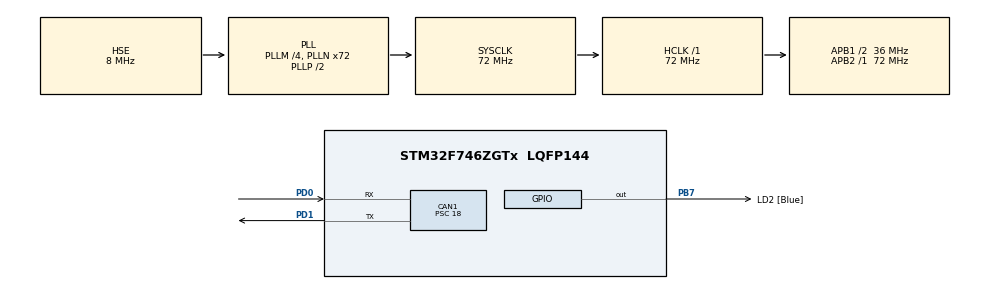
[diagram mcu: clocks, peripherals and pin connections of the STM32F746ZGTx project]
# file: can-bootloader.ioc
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CAN1.BS1=CAN_BS1_13TQ
CAN1.BS2=CAN_BS2_2TQ
CAN1.CalculateBaudRate=125000
CAN1.CalculateTimeBit=8000
CAN1.CalculateTimeQuantum=500.0
CAN1.NART=ENABLE
CAN1.Prescaler=18
CORTEX_M7.default_mode_Activation=1
CRC.InputDataFormat=CRC_INPUTDATA_FORMAT_WORDS
Mcu.Family=STM32F7
Mcu.Name=STM32F746ZGTx
Mcu.Package=LQFP144
NVIC.CAN1_RX0_IRQn=true\:0\:0\:false\:false\:true\:true\:true\:true
NVIC.CAN1_TX_IRQn=true\:0\:0\:false\:false\:true\:true\:true\:true
NVIC.PriorityGroup=NVIC_PRIORITYGROUP_4
NVIC.TIM6_DAC_IRQn=true\:0\:0\:false\:false\:true\:true\:true\:true
PA13.GPIO_Label=TMS
PA13.Mode=Serial_Wire
PA13.Signal=SYS_JTMS-SWDIO
PA14.GPIO_Label=TCK
PA14.Mode=Serial_Wire
PA14.Signal=SYS_JTCK-SWCLK
PB7.GPIO_Label=LD2 [Blue]
PB7.Signal=GPIO_Output
PD0.Mode=CAN_Activate
PD0.Signal=CAN1_RX
PD1.Mode=CAN_Activate
PD1.Signal=CAN1_TX
PH0/OSC_IN.GPIO_Label=MCO [STM32F103CBT6_PA8]
PH0/OSC_IN.Mode=HSE-External-Clock-Source
PH0/OSC_IN.Signal=RCC_OSC_IN
PH1/OSC_OUT.Mode=HSE-External-Clock-Source
PH1/OSC_OUT.Signal=RCC_OSC_OUT
ProjectManager.HeapSize=0x200
ProjectManager.StackSize=0x400
ProjectManager.TargetToolchain=CMake
RCC.48MHZClocksFreq_Value=24000000
RCC.AHBFreq_Value=72000000
RCC.APB1CLKDivider=RCC_HCLK_DIV2
RCC.APB1Freq_Value=36000000
RCC.APB1TimFreq_Value=72000000
RCC.APB2Freq_Value=72000000
RCC.APB2TimFreq_Value=72000000
RCC.CortexFreq_Value=72000000
RCC.HCLKFreq_Value=72000000
RCC.HSE_VALUE=8000000
RCC.HSI_VALUE=16000000
RCC.LSE_VALUE=32768
RCC.PLLM=4
RCC.PLLMUL=RCC_PLL_MUL9
RCC.PLLN=72
RCC.PLLQ=3
RCC.PLLSourceVirtual=RCC_PLLSOURCE_HSE
RCC.PRESCALERUSB=RCC_USBCLKSOURCE_PLL_DIV1_5
RCC.SYSCLKFreq_VALUE=72000000
RCC.SYSCLKSource=RCC_SYSCLKSOURCE_PLLCLK
RCC.SYSCLKSourceVirtual=RCC_SYSCLKSOURCE_PLLCLK
RCC.USBFreq_Value=48000000
RCC.VCOOutputFreq_Value=144000000
TIM6.Period=49999
TIM6.Prescaler=7199
VP_CRC_VS_CRC.Mode=CRC_Activate
VP_TIM6_VS_ClockSourceINT.Mode=Enable_Timer
board=NUCLEO-F746ZG

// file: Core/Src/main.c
/* USER CODE BEGIN Header */
/**
  ******************************************************************************
  * @file           : main.c
  * @brief          : Main program body
  ******************************************************************************
  * @attention
  *
  * Copyright (c) 2026 STMicroelectronics.
  * All rights reserved.
  *
  * This software is licensed under terms that can be found in the LICENSE file
  * in the root directory of this software component.
  * If no LICENSE file comes with this software, it is provided AS-IS.
  *
  ******************************************************************************
  */
/* USER CODE END Header */
#include "main.h"

/* USER CODE BEGIN Includes */
#include "boot_utility.h"
#include "can_utility.h"
#include "flash_utility.h"
#include "string.h"
/* USER CODE END Includes */

CAN_HandleTypeDef hcan1;

CRC_HandleTypeDef hcrc;

TIM_HandleTypeDef htim6;

void SystemClock_Config(void);
static void MPU_Config(void);
static void MX_GPIO_Init(void);
static void MX_CAN1_Init(void);
static void MX_TIM6_Init(void);
static void MX_CRC_Init(void);

/* USER CODE BEGIN 0 */
// If timer gets reset, it means no CAN frame arrived in the last 5s
void HAL_TIM_PeriodElapsedCallback(TIM_HandleTypeDef *htim)
{
  if (htim->Instance == TIM6)
  {
    abort_required = 1;
  }
}
/* USER CODE END 0 */

int main(void)
{

  /* USER CODE BEGIN 1 */
  HAL_StatusTypeDef res;
  /* USER CODE END 1 */

  /* MPU Configuration--------------------------------------------------------*/
  MPU_Config();

  /* MCU Configuration--------------------------------------------------------*/

  /* Reset of all peripherals, Initializes the Flash interface and the Systick. */
  HAL_Init();

  /* Configure the system clock */
  SystemClock_Config();

  /* Initialize all configured peripherals */
  MX_GPIO_Init();
  MX_CAN1_Init();
  MX_TIM6_Init();
  MX_CRC_Init();
  /* USER CODE BEGIN 2 */
  HAL_CAN_Start(&hcan1);
  /* USER CODE END 2 */

  /* Infinite loop */
  /* USER CODE BEGIN WHILE */
  // Initialize CAN receive buffer
  memset((void*)can_rx_buffer, 0xFF, CAN_RX_BUFFER_SIZE);

  // Confirm to gateway board that bootloader is ready
  res = CAN_Send_ControlFrame(&hcan1, CAN_MAILBOX_TX_DEFAULT_TIMEOUT);
  if (res != HAL_OK) {
    Boot_Recover();
  }

  // Start expecting CAN communication with gateway board
  res = HAL_TIM_Base_Start_IT(&htim6);
  if (res != HAL_OK) {
    Boot_Recover();
  }

  while (1)
  {
    if (setup_request) {
      // Gateway board requested bootloader setup
#ifdef TWO_SLOT_SOLUTION
      res = Flash_Erase_TargetSlot(SWAP_SLOT);
#else
      res = Flash_Erase_TargetSlot(USER_APP_SLOT);
#endif
      if (res != HAL_OK) {
        Boot_Recover();
      }

      res = CAN_Send_ControlFrame(&hcan1, CAN_MAILBOX_TX_DEFAULT_TIMEOUT);
      if (res != HAL_OK) {
        Boot_Recover();
      }

      // Setup handled successfully
      setup_request = 0;
    }

    if (app_ready) {
      // Turn off timer
      HAL_TIM_Base_Stop_IT(&htim6);

#ifdef TWO_SLOT_SOLUTION
      // Move contents of the new app from swap space to user application space
      res = Flash_Move_Swap();
      if (res != HAL_OK) {
          Boot_Recover();
      }
#endif

      // Confirm to gateway board that flashing was a success
      res = CAN_Send_ControlFrame(&hcan1, CAN_MAILBOX_TX_DEFAULT_TIMEOUT);
      if (res != HAL_OK) {
        Boot_Recover();
      }

      Boot_Start_UserApplication();
    }

    if (abort_required) {
      // Turn off timer
      HAL_TIM_Base_Stop_IT(&htim6);

      Boot_Recover();
    }

    HAL_GPIO_TogglePin(LD2_GPIO_Port, LD2_Pin);
    HAL_Delay(100);
    HAL_GPIO_TogglePin(LD2_GPIO_Port, LD2_Pin);
    HAL_Delay(100);
    /* USER CODE END WHILE */

  }
}

void SystemClock_Config(void)
{
  RCC_OscInitTypeDef RCC_OscInitStruct = {0};
  RCC_ClkInitTypeDef RCC_ClkInitStruct = {0};

  /** Configure the main internal regulator output voltage
  */
  __HAL_RCC_PWR_CLK_ENABLE();
  __HAL_PWR_VOLTAGESCALING_CONFIG(PWR_REGULATOR_VOLTAGE_SCALE3);

  /** Initializes the RCC Oscillators according to the specified parameters
  * in the RCC_OscInitTypeDef structure.
  */
  RCC_OscInitStruct.OscillatorType = RCC_OSCILLATORTYPE_HSE;
  RCC_OscInitStruct.HSEState = RCC_HSE_BYPASS;
  RCC_OscInitStruct.PLL.PLLState = RCC_PLL_ON;
  RCC_OscInitStruct.PLL.PLLSource = RCC_PLLSOURCE_HSE;
  RCC_OscInitStruct.PLL.PLLM = 4;
  RCC_OscInitStruct.PLL.PLLN = 72;
  RCC_OscInitStruct.PLL.PLLP = RCC_PLLP_DIV2;
  RCC_OscInitStruct.PLL.PLLQ = 3;
  if (HAL_RCC_OscConfig(&RCC_OscInitStruct) != HAL_OK)
  {
    Error_Handler();
  }

  /** Initializes the CPU, AHB and APB buses clocks
  */
  RCC_ClkInitStruct.ClockType = RCC_CLOCKTYPE_HCLK|RCC_CLOCKTYPE_SYSCLK
                              |RCC_CLOCKTYPE_PCLK1|RCC_CLOCKTYPE_PCLK2;
  RCC_ClkInitStruct.SYSCLKSource = RCC_SYSCLKSOURCE_PLLCLK;
  RCC_ClkInitStruct.AHBCLKDivider = RCC_SYSCLK_DIV1;
  RCC_ClkInitStruct.APB1CLKDivider = RCC_HCLK_DIV2;
  RCC_ClkInitStruct.APB2CLKDivider = RCC_HCLK_DIV1;

  if (HAL_RCC_ClockConfig(&RCC_ClkInitStruct, FLASH_LATENCY_2) != HAL_OK)
  {
    Error_Handler();
  }
}

static void MX_CAN1_Init(void)
{

  hcan1.Instance = CAN1;
  hcan1.Init.Prescaler = 18;
  hcan1.Init.Mode = CAN_MODE_NORMAL;
  hcan1.Init.SyncJumpWidth = CAN_SJW_1TQ;
  hcan1.Init.TimeSeg1 = CAN_BS1_13TQ;
  hcan1.Init.TimeSeg2 = CAN_BS2_2TQ;
  hcan1.Init.TimeTriggeredMode = DISABLE;
  hcan1.Init.AutoBusOff = DISABLE;
  hcan1.Init.AutoWakeUp = DISABLE;
  hcan1.Init.AutoRetransmission = ENABLE;
  hcan1.Init.ReceiveFifoLocked = DISABLE;
  hcan1.Init.TransmitFifoPriority = DISABLE;
  if (HAL_CAN_Init(&hcan1) != HAL_OK)
  {
    Error_Handler();
  }
  /* USER CODE BEGIN CAN1_Init 2 */
  CAN_FilterTypeDef filter;

  filter.FilterActivation = ENABLE;
  filter.FilterBank = 0;
  filter.FilterFIFOAssignment = CAN_FILTER_FIFO0;
  filter.FilterIdHigh = 0x0000;
  filter.FilterIdLow = 0x0000;
  filter.FilterMaskIdHigh = 0x0000;
  filter.FilterMaskIdLow = 0x0000;
  filter.FilterMode = CAN_FILTERMODE_IDMASK;
  filter.FilterScale = CAN_FILTERSCALE_32BIT;

  HAL_CAN_ConfigFilter(&hcan1, &filter);
  HAL_CAN_ActivateNotification(&hcan1, CAN_IT_RX_FIFO0_MSG_PENDING);

  /* USER CODE END CAN1_Init 2 */

}

static void MX_CRC_Init(void)
{

  hcrc.Instance = CRC;
  hcrc.Init.DefaultPolynomialUse = DEFAULT_POLYNOMIAL_ENABLE;
  hcrc.Init.DefaultInitValueUse = DEFAULT_INIT_VALUE_ENABLE;
  hcrc.Init.InputDataInversionMode = CRC_INPUTDATA_INVERSION_NONE;
  hcrc.Init.OutputDataInversionMode = CRC_OUTPUTDATA_INVERSION_DISABLE;
  hcrc.InputDataFormat = CRC_INPUTDATA_FORMAT_WORDS;
  if (HAL_CRC_Init(&hcrc) != HAL_OK)
  {
    Error_Handler();
  }

}

static void MX_TIM6_Init(void)
{

  TIM_MasterConfigTypeDef sMasterConfig = {0};

  htim6.Instance = TIM6;
  htim6.Init.Prescaler = 7199;
  htim6.Init.CounterMode = TIM_COUNTERMODE_UP;
  htim6.Init.Period = 49999;
  htim6.Init.AutoReloadPreload = TIM_AUTORELOAD_PRELOAD_DISABLE;
  if (HAL_TIM_Base_Init(&htim6) != HAL_OK)
  {
    Error_Handler();
  }
  sMasterConfig.MasterOutputTrigger = TIM_TRGO_RESET;
  sMasterConfig.MasterSlaveMode = TIM_MASTERSLAVEMODE_DISABLE;
  if (HAL_TIMEx_MasterConfigSynchronization(&htim6, &sMasterConfig) != HAL_OK)
  {
    Error_Handler();
  }

}

static void MX_GPIO_Init(void)
{
  GPIO_InitTypeDef GPIO_InitStruct = {0};

  /* GPIO Ports Clock Enable */
  __HAL_RCC_GPIOH_CLK_ENABLE();
  __HAL_RCC_GPIOA_CLK_ENABLE();
  __HAL_RCC_GPIOD_CLK_ENABLE();
  __HAL_RCC_GPIOB_CLK_ENABLE();

  /*Configure GPIO pin Output Level */
  HAL_GPIO_WritePin(LD2_GPIO_Port, LD2_Pin, GPIO_PIN_RESET);

  /*Configure GPIO pin : LD2_Pin */
  GPIO_InitStruct.Pin = LD2_Pin;
  GPIO_InitStruct.Mode = GPIO_MODE_OUTPUT_PP;
  GPIO_InitStruct.Pull = GPIO_NOPULL;
  GPIO_InitStruct.Speed = GPIO_SPEED_FREQ_LOW;
  HAL_GPIO_Init(LD2_GPIO_Port, &GPIO_InitStruct);

}

 /* MPU Configuration */

void MPU_Config(void)
{
  MPU_Region_InitTypeDef MPU_InitStruct = {0};

  /* Disables the MPU */
  HAL_MPU_Disable();

  /** Initializes and configures the Region and the memory to be protected
  */
  MPU_InitStruct.Enable = MPU_REGION_ENABLE;
  MPU_InitStruct.Number = MPU_REGION_NUMBER0;
  MPU_InitStruct.BaseAddress = 0x0;
  MPU_InitStruct.Size = MPU_REGION_SIZE_4GB;
  MPU_InitStruct.SubRegionDisable = 0x87;
  MPU_InitStruct.TypeExtField = MPU_TEX_LEVEL0;
  MPU_InitStruct.AccessPermission = MPU_REGION_NO_ACCESS;
  MPU_InitStruct.DisableExec = MPU_INSTRUCTION_ACCESS_DISABLE;
  MPU_InitStruct.IsShareable = MPU_ACCESS_SHAREABLE;
  MPU_InitStruct.IsCacheable = MPU_ACCESS_NOT_CACHEABLE;
  MPU_InitStruct.IsBufferable = MPU_ACCESS_NOT_BUFFERABLE;

  HAL_MPU_ConfigRegion(&MPU_InitStruct);
  /* Enables the MPU */
  HAL_MPU_Enable(MPU_PRIVILEGED_DEFAULT);

}

void Error_Handler(void)
{
  __disable_irq();
  while (1)
  {
  }
}
